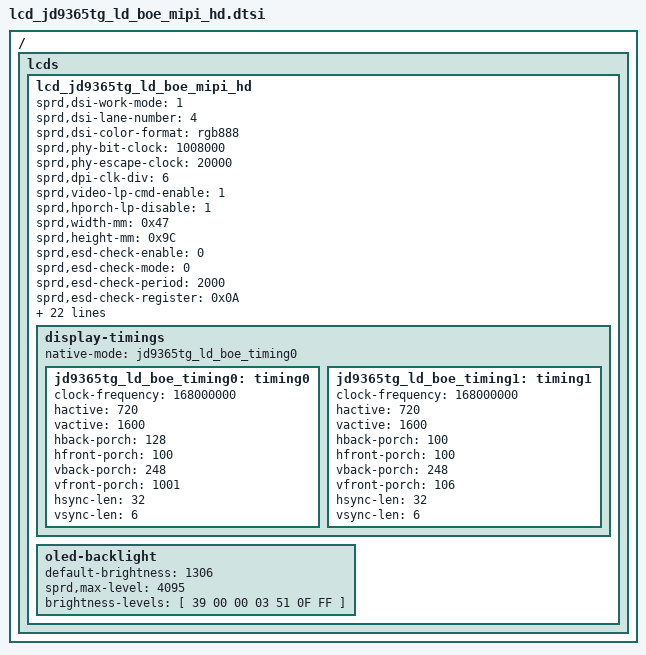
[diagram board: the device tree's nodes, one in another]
/*
 * R61350 Truly LCD config dtsi file for spreadtrum
 *
 * Copyright (C) 2018, Spreadtrum Communications Inc.
 *
 * SPDX-License-Identifier: (GPL-2.0+ OR MIT)
 */

/ {
	fragment {
		target-path = "/";
		__overlay__ {
			lcds {
				lcd_jd9365tg_ld_boe_mipi_hd: lcd_jd9365tg_ld_boe_mipi_hd {

					sprd,dsi-work-mode = <1>; /* video burst mode*/
					sprd,dsi-lane-number = <4>;
					sprd,dsi-color-format = "rgb888";

					sprd,phy-bit-clock = <1008000>;	/* kbps */
					sprd,phy-escape-clock = <20000>;/* kHz */
					sprd,dpi-clk-div = <6>;
					sprd,video-lp-cmd-enable = <1>;
					sprd,hporch-lp-disable = <1>;

					sprd,width-mm = <0x47>;
					sprd,height-mm = <0x9C>;
					sprd,esd-check-enable = <0>;
					sprd,esd-check-mode = <0>;
					sprd,esd-check-period = <2000>;
					sprd,esd-check-register = <0x0A>;
					sprd,esd-check-value = <0x1C>;

					sprd,power-i2c-bus = <4>;
					sprd,power-i2c-addr = <0x3e>;
					sprd,power-i2c-reg = [00 01 03];
					sprd,power-i2c-val = [12 12 43];

					sprd,reset-on-sequence = <1 5>, <0 10>, <1 120>;
					sprd,reset-off-sequence = <0 5>;

					/*
					 * Use 4 bits number for descripting video lp mode, and it can be combined used.
					 * BIT(0): allow vactive enter lp;
					 * BIT(1): allow vfp enter lp;
					 * BIT(2): allow vbp enter lp;
					 * BIT(3): allow vsa enter lp;
					 * For example:
					 * If we need vfp & vbp enter lp, we can calculate this value as a result of BIT(1) | BIT(2)
					 * And we get the result of 3 and set this value to lcd dt property sprd,video-lp-en-mode.
					 * If we need all stage can enter lp, we can calculate this value as a result of BIT(0) | BIT(1) | BIT(2) | BIT(3).
					 * And we get the result of 15 and set this value to lcd dt property sprd,video-lp-en-mode.
					 */
					sprd,video-lp-en-mode = <2>;
					sprd,use-dcs-write;
					sprd,initial-command = [
					39 00 00 04 DF 93 89 1C
					39 00 00 02 DE 00
					39 00 00 08 B2 01 23 60 88 24 5A 07
					39 00 00 08 BB 0F 12 43 50 5A 44 44
					39 00 00 03 BF 46 5A
					39 00 00 05 C0 00 D5 00 D5
					39 00 00 03 BD 00 CE
					39 00 00 18 C6 00 56 00 C8 00 13 28 82 00 00 00 01 00 01 00 00 00 00 00 01 00 00 01
					39 00 00 04 C8 30 20 B4
					39 00 00 02 CC 33
					39 00 00 04 BC 2E 80 84
					39 00 00 1A C3 3B 01 00 03 08 08 50 05 53 05 53 01 4C 01 4C 01 4C 06 4E 06 09 06 09 06 09
					39 00 00 19 C4 01 00 03 08 08 50 05 53 05 53 01 4C 01 4C 01 4C 06 4E 06 09 06 09 06 09
					39 00 00 18 C5 03 03 08 08 50 05 53 05 53 01 4C 01 4C 01 4C 06 4E 06 09 06 09 06 09
					39 00 00 10 D7 00 35 35 35 35 35 35 35 35 35 35 35 35 35 35
					39 00 00 2C CB 72 6A 61 53 48 46 37 3C 27 41 40 3F 5B 48 4F 41 3F 32 22 17 06 72 6A 61 53 48 46 37 3C 27 41 40 3F 5B 48 4F 41 3F 32 22 17 06 00
					39 00 00 18 CE 00 0C 0C 0F 0C 0C 0C 0C 0C 0C 0C 0C 0C 0C 0C 0C 0C 0C 0C 0C 0C 0C 0C
					39 00 00 34 CF 00 30 30 30 30 30 30 30 30 30 30 30 30 30 30 30 30 30 30 30 30 30 30 00 00 00 00 00 00 00 00 00 00 00 00 00 00 00 00 00 00 00 00 00 00 FF FF FF FF FF 3F
					39 00 00 1E D0 00 1F 1F 15 1F 00 02 08 0A 04 06 15 15 1F 1F 1F 1F 1F 1F 1F 1F 1F 1F 00 00 00 00 00 00
					39 00 00 1E D1 00 1F 1F 15 1F 01 03 09 0B 05 07 15 15 1F 1F 1F 1F 1F 1F 1F 1F 1F 1F 00 00 00 00 00 00
					39 00 00 18 D2 00 1F 1E 15 1F 03 01 07 05 0B 09 1F 15 1F 1F 1F 1F 1F 1F 1F 1F 1F 1F
					39 00 00 18 D3 00 1F 1E 15 1F 02 00 06 04 0A 08 1F 15 1F 1F 1F 1F 1F 1F 1F 1F 1F 1F
					39 00 00 59 D4 00 60 08 00 0A 00 0E 00 00 00 00 00 00 00 00 00 00 04 04 04 00 83 06 55 06 57 06 59 00 00 00 00 00 00 00 00 00 03 03 03 03 03 03 00 00 00 00 00 03 03 00 80 0A 00 0A 06 50 06 4B 00 00 00 00 00 00 00 00 02 00 00 00 00 00 00 00 00 00 00 00 40 00 00 03 00 00 20 00 00
					39 00 00 3F D5 02 10 01 00 00 00 00 00 00 E0 00 00 00 07 32 5A 00 00 01 00 00 00 00 74 00 0C 00 08 00 71 20 04 10 04 06 00 00 00 00 00 00 00 00 FF FF 00 00 1F FF 00 00 00 1F FF 00 FF FF FF FF FF FF 00
					39 00 00 03 CD 08 00
					39 00 00 02 DE 01
					39 00 00 06 B5 64 00 00 00 00
					39 00 00 1E B7 36 13 D2 D6 DB DF E2 E3 E4 EF FC A0 B0 B0 B0 B0 B0 B1 D6 E0 A6 A6 A6 A6 A7 A8 A9 DC DE
					39 00 00 05 B9 00 FF FF 04
					39 00 00 03 BF 00 0C
					39 00 00 04 C7 1F 14 0E
					39 00 00 07 BE 01 7C 82 26 00 BF
					39 00 00 02 DE 02
					39 00 00 05 BF 05 10 00 00
					39 00 00 19 E5 00 90 90 02 23 73 23 73 09 04 00 C5 01 2C 04 00 00 00 00 00 04 00 00 04
					39 00 00 07 E6 14 09 25 00 00 00
					39 00 00 08 C4 00 11 07 00 20 01 08
					39 00 00 03 C3 20 FF
					39 00 00 02 BD 1B
					39 00 00 03 C6 4F 00
					39 00 00 05 CD 14 64 11 40
					39 00 00 0B C1 00 40 00 02 02 02 02 7F 00 00
					39 00 00 0F EC 07 07 40 00 22 02 00 FF 08 7C 00 00 00 00
					39 00 00 02 DE 03
					39 00 00 06 D1 00 00 21 FF 80
					39 00 00 02 DE 00
					39 00 00 03 51 00 88
					39 00 00 02 53 2C
					39 00 00 02 35 00
					05 78 00 01 11
					05 01 00 01 29
					];

					sprd,sleep-in-command = [
					39 02 00 02 DE 00
					05 32 00 01 28
					05 78 00 01 10
					];

					sprd,sleep-in-command-gesture-off = [
					39 02 00 02 DE 00
					05 32 00 01 28
					05 78 00 01 10
					];

					sprd,sleep-out-command = [
					05 64 00 01 11
					05 14 00 01 29
					];

					sprd,cabc-off-command = [
					23 00 00 02 55 00
					];
					sprd,cabc-ui-command = [
					23 00 00 02 55 01
					];
					sprd,cabc-still-command = [
					23 00 00 02 55 02
					];
					sprd,cabc-moving-command = [
					23 00 00 02 55 03
					];


					display-timings {
						native-mode = <&jd9365tg_ld_boe_timing0>;

						jd9365tg_ld_boe_timing0: timing0 {
							clock-frequency = <168000000>;
							hactive = <720>;
							vactive = <1600>;
							hback-porch = <128>;
							hfront-porch = <100>;
							vback-porch = <248>;
							vfront-porch = <1001>;
							hsync-len = <32>;
							vsync-len = <6>;
						};
						jd9365tg_ld_boe_timing1: timing1 {
							clock-frequency = <168000000>;
							hactive = <720>;
							vactive = <1600>;
							hback-porch = <100>;
							hfront-porch = <100>;
							vback-porch = <248>;
							vfront-porch = <106>;
							hsync-len = <32>;
							vsync-len = <6>;
						};
					};

					oled-backlight {
						default-brightness = <1306>;
						sprd,max-level = <4095>;
						brightness-levels = [
						39 00 00 03 51 0F FF
						];
					};
				};
			};
		};
	};
};
